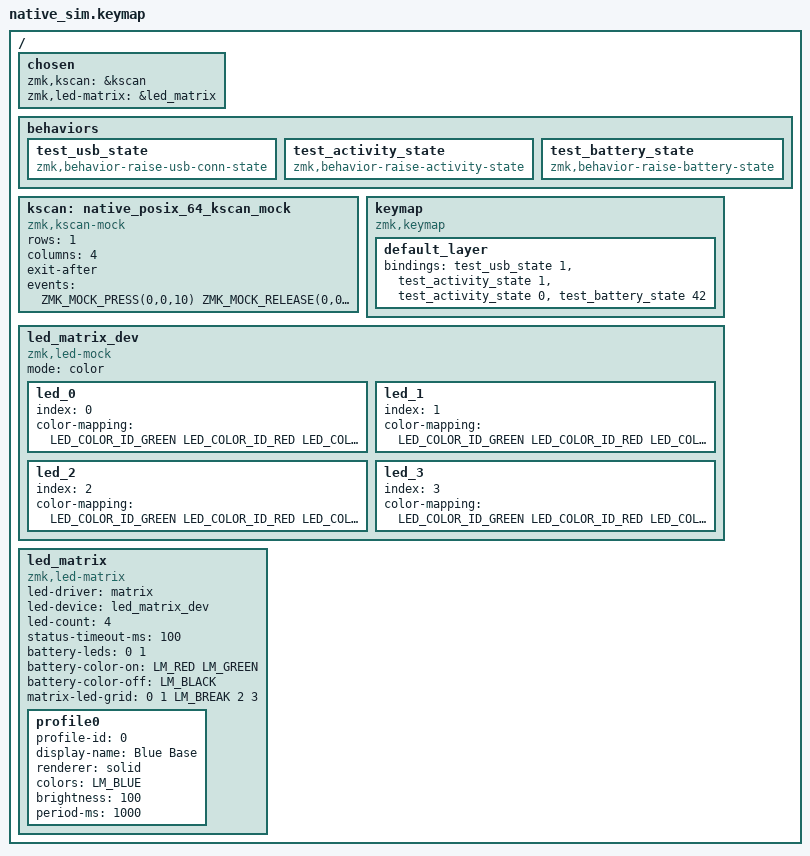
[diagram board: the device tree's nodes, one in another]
#include <dt-bindings/zmk/keys.h>
#include <dt-bindings/zmk/kscan_mock.h>
#include <dt-bindings/zmk/led_matrix.h>
#include <dt-bindings/zmk/led_matrix_colors.h>
#include <dt-bindings/led/led.h>
#include <behaviors.dtsi>

/ {
    chosen {
        zmk,kscan = &kscan;
        zmk,led-matrix = &led_matrix;
    };

    behaviors {
        test_usb_state: test_usb_state {
            compatible = "zmk,behavior-raise-usb-conn-state";
            #binding-cells = <1>;
        };

        test_activity_state: test_activity_state {
            compatible = "zmk,behavior-raise-activity-state";
            #binding-cells = <1>;
        };

        test_battery_state: test_battery_state {
            compatible = "zmk,behavior-raise-battery-state";
            #binding-cells = <1>;
        };
    };

    kscan: native_posix_64_kscan_mock {
        compatible = "zmk,kscan-mock";
        rows = <1>;
        columns = <4>;
        exit-after;
        events = <
            ZMK_MOCK_PRESS(0,0,10)
            ZMK_MOCK_RELEASE(0,0,150)
            ZMK_MOCK_PRESS(0,1,10)
            ZMK_MOCK_RELEASE(0,1,10)
            ZMK_MOCK_PRESS(0,2,10)
            ZMK_MOCK_RELEASE(0,2,10)
            ZMK_MOCK_PRESS(0,3,10)
            ZMK_MOCK_RELEASE(0,3,10)
        >;
    };

    keymap {
        compatible = "zmk,keymap";

        default_layer {
            bindings = <
                &test_usb_state 1 &test_activity_state 1 &test_activity_state 0 &test_battery_state 42
            >;
        };
    };

    led_matrix_dev: led_matrix_dev {
        compatible = "zmk,led-mock";
        mode = "color";

        led_0 { index = <0>; color-mapping = <LED_COLOR_ID_GREEN LED_COLOR_ID_RED LED_COLOR_ID_BLUE>; };
        led_1 { index = <1>; color-mapping = <LED_COLOR_ID_GREEN LED_COLOR_ID_RED LED_COLOR_ID_BLUE>; };
        led_2 { index = <2>; color-mapping = <LED_COLOR_ID_GREEN LED_COLOR_ID_RED LED_COLOR_ID_BLUE>; };
        led_3 { index = <3>; color-mapping = <LED_COLOR_ID_GREEN LED_COLOR_ID_RED LED_COLOR_ID_BLUE>; };
    };

    led_matrix: led_matrix {
        compatible = "zmk,led-matrix";
        led-driver = "matrix";
        led-device = <&led_matrix_dev>;
        led-count = <4>;
        status-timeout-ms = <100>;
        battery-leds = <0 1>;
        battery-color-on = <LM_RED LM_GREEN>;
        battery-color-off = <LM_BLACK>;
        matrix-led-grid = <
            0 1 LM_BREAK
            2 3
        >;

        profile0 {
            profile-id = <0>;
            display-name = "Blue Base";
            renderer = "solid";
            colors = <LM_BLUE>;
            brightness = <100>;
            period-ms = <1000>;
        };
    };
};
